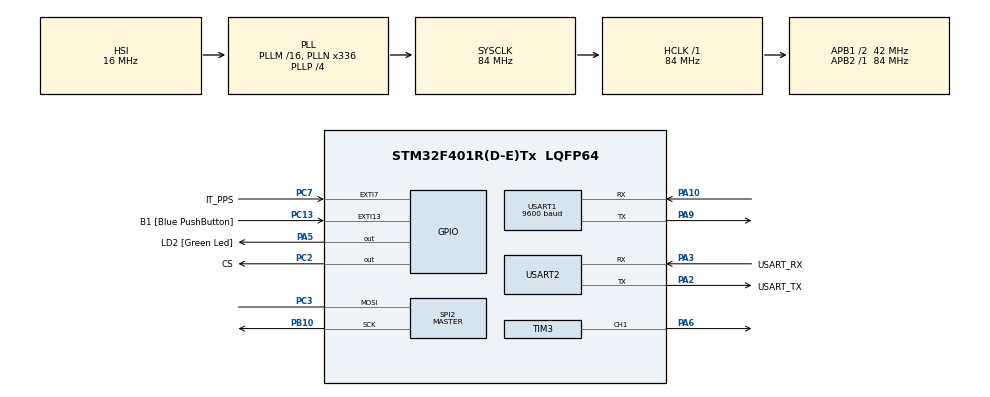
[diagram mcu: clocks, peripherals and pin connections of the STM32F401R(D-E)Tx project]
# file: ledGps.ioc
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Mcu.Family=STM32F4
Mcu.Name=STM32F401R(D-E)Tx
Mcu.Package=LQFP64
NVIC.EXTI9_5_IRQn=true\:0\:0\:false\:false\:true\:true\:true
NVIC.PriorityGroup=NVIC_PRIORITYGROUP_0
NVIC.TIM3_IRQn=true\:0\:0\:false\:false\:true\:true\:true
PA10.Mode=Asynchronous
PA10.Signal=USART1_RX
PA13.GPIO_Label=TMS
PA13.Mode=Serial_Wire
PA13.Signal=SYS_JTMS-SWDIO
PA14.GPIO_Label=TCK
PA14.Mode=Serial_Wire
PA14.Signal=SYS_JTCK-SWCLK
PA2.GPIO_Label=USART_TX
PA2.GPIO_Mode=GPIO_MODE_AF_PP
PA2.GPIO_PuPd=GPIO_NOPULL
PA2.GPIO_Speed=GPIO_SPEED_FREQ_LOW
PA2.Mode=Asynchronous
PA2.Signal=USART2_TX
PA3.GPIO_Label=USART_RX
PA3.GPIO_Mode=GPIO_MODE_AF_PP
PA3.GPIO_PuPd=GPIO_NOPULL
PA3.GPIO_Speed=GPIO_SPEED_FREQ_LOW
PA3.Mode=Asynchronous
PA3.Signal=USART2_RX
PA5.GPIO_Label=LD2 [Green Led]
PA5.GPIO_Mode=GPIO_MODE_OUTPUT_PP
PA5.GPIO_PuPd=GPIO_NOPULL
PA5.GPIO_Speed=GPIO_SPEED_FREQ_LOW
PA5.Signal=GPIO_Output
PA6.Signal=S_TIM3_CH1
PA9.Mode=Asynchronous
PA9.Signal=USART1_TX
PB10.Mode=Simplex_Bidirectional_Master
PB10.Signal=SPI2_SCK
PB3.GPIO_Label=SWO
PB3.Signal=SYS_JTDO-SWO
PC13-ANTI_TAMP.GPIO_Label=B1 [Blue PushButton]
PC13-ANTI_TAMP.GPIO_ModeDefaultEXTI=GPIO_MODE_IT_FALLING
PC13-ANTI_TAMP.GPIO_PuPd=GPIO_NOPULL
PC13-ANTI_TAMP.Signal=GPXTI13
PC14-OSC32_IN.Mode=LSE-External-Oscillator
PC14-OSC32_IN.Signal=RCC_OSC32_IN
PC15-OSC32_OUT.Mode=LSE-External-Oscillator
PC15-OSC32_OUT.Signal=RCC_OSC32_OUT
PC2.GPIO_Label=CS
PC2.GPIO_Speed=GPIO_SPEED_FREQ_VERY_HIGH
PC2.Signal=GPIO_Output
PC3.Mode=Simplex_Bidirectional_Master
PC3.Signal=SPI2_MOSI
PC7.GPIO_Label=IT_PPS
PC7.GPIO_ModeDefaultEXTI=GPIO_MODE_IT_RISING
PC7.Signal=GPXTI7
PH0\ -\ OSC_IN.Mode=HSE-External-Clock-Source
PH0\ -\ OSC_IN.Signal=RCC_OSC_IN
PH1\ -\ OSC_OUT.Mode=HSE-External-Clock-Source
PH1\ -\ OSC_OUT.Signal=RCC_OSC_OUT
ProjectManager.HeapSize=0x200
ProjectManager.StackSize=0x400
ProjectManager.TargetToolchain=Makefile
RCC.48MHZClocksFreq_Value=48000000
RCC.AHBFreq_Value=84000000
RCC.APB1CLKDivider=RCC_HCLK_DIV2
RCC.APB1Freq_Value=42000000
RCC.APB1TimFreq_Value=84000000
RCC.APB2Freq_Value=84000000
RCC.APB2TimFreq_Value=84000000
RCC.CortexFreq_Value=84000000
RCC.HCLKFreq_Value=84000000
RCC.HSE_VALUE=8000000
RCC.HSI_VALUE=16000000
RCC.PLLN=336
RCC.PLLP=RCC_PLLP_DIV4
RCC.PLLQ=7
RCC.SYSCLKFreq_VALUE=84000000
RCC.SYSCLKSource=RCC_SYSCLKSOURCE_PLLCLK
RCC.VCOOutputFreq_Value=336000000
SH.S_TIM3_CH1.0=TIM3_CH1,PWM Generation1 CH1
SPI2.BaudRatePrescaler=SPI_BAUDRATEPRESCALER_128
SPI2.DataSize=SPI_DATASIZE_16BIT
SPI2.Direction=SPI_DIRECTION_1LINE
SPI2.Mode=SPI_MODE_MASTER
SPI2.VirtualType=VM_MASTER
TIM3.Channel-PWM\ Generation1\ CH1=TIM_CHANNEL_1
TIM3.OCFastMode_PWM-PWM\ Generation1\ CH1=TIM_OCFAST_ENABLE
TIM3.Period=10-1
TIM3.Prescaler=840
TIM3.Pulse-PWM\ Generation1\ CH1=5
USART1.BaudRate=9600
USART1.VirtualMode=VM_ASYNC
USART2.VirtualMode=VM_ASYNC
VP_TIM3_VS_ClockSourceINT.Mode=Internal
board=NUCLEO-F401RE

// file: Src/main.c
/* USER CODE BEGIN Header */
/**
  ******************************************************************************
  * @file           : main.c
  * @brief          : Main program body
  ******************************************************************************
  ** This notice applies to any and all portions of this file
  * that are not between comment pairs USER CODE BEGIN and
  * USER CODE END. Other portions of this file, whether
  * inserted by the user or by software development tools
  * are owned by their respective copyright owners.
  *
  * COPYRIGHT(c) 2019 STMicroelectronics
  *
  * Redistribution and use in source and binary forms, with or without modification,
  * are permitted provided that the following conditions are met:
  *   1. Redistributions of source code must retain the above copyright notice,
  *      this list of conditions and the following disclaimer.
  *   2. Redistributions in binary form must reproduce the above copyright notice,
  *      this list of conditions and the following disclaimer in the documentation
  *      and/or other materials provided with the distribution.
  *   3. Neither the name of STMicroelectronics nor the names of its contributors
  *      may be used to endorse or promote products derived from this software
  *      without specific prior written permission.
  *
  * THIS SOFTWARE IS PROVIDED BY THE COPYRIGHT HOLDERS AND CONTRIBUTORS "AS IS"
  * AND ANY EXPRESS OR IMPLIED WARRANTIES, INCLUDING, BUT NOT LIMITED TO, THE
  * IMPLIED WARRANTIES OF MERCHANTABILITY AND FITNESS FOR A PARTICULAR PURPOSE ARE
  * DISCLAIMED. IN NO EVENT SHALL THE COPYRIGHT HOLDER OR CONTRIBUTORS BE LIABLE
  * FOR ANY DIRECT, INDIRECT, INCIDENTAL, SPECIAL, EXEMPLARY, OR CONSEQUENTIAL
  * DAMAGES (INCLUDING, BUT NOT LIMITED TO, PROCUREMENT OF SUBSTITUTE GOODS OR
  * SERVICES; LOSS OF USE, DATA, OR PROFITS; OR BUSINESS INTERRUPTION) HOWEVER
  * CAUSED AND ON ANY THEORY OF LIABILITY, WHETHER IN CONTRACT, STRICT LIABILITY,
  * OR TORT (INCLUDING NEGLIGENCE OR OTHERWISE) ARISING IN ANY WAY OUT OF THE USE
  * OF THIS SOFTWARE, EVEN IF ADVISED OF THE POSSIBILITY OF SUCH DAMAGE.
  *
  ******************************************************************************
  */
/* USER CODE END Header */

#include "main.h"
#include "gpio.h"
#include "spi.h"
#include "tim.h"
#include "usart.h"

/* USER CODE BEGIN Includes */
#include "7seg.h"
#include "Gps.h"
#include <stdlib.h>
/* USER CODE END Includes */

void SystemClock_Config(void);

char message[80] = "\0";
int main(void)
{
    /* USER CODE BEGIN 1 */
    token = (char*)calloc(6, sizeof(char));
    char data[] = "441";
    char* ggaParsed;
    /* USER CODE END 1 */

    /* MCU Configuration--------------------------------------------------------*/

    /* Reset of all peripherals, Initializes the Flash interface and the Systick. */
    HAL_Init();

    /* Configure the system clock */
    SystemClock_Config();

    /* Initialize all configured peripherals */
    MX_GPIO_Init();
    MX_USART2_UART_Init();
    MX_USART1_UART_Init();
    MX_SPI2_Init();
    MX_TIM3_Init();
    /* USER CODE BEGIN 2 */
    HAL_TIM_Base_Start_IT(&htim3);
    /* USER CODE END 2 */

    /* Infinite loop */
    /* USER CODE BEGIN WHILE */
    HAL_GPIO_WritePin(seg_pin.cs_port, seg_pin.cs_pin, 1);
    setupSeg(seg_pin);
    while (1)
    {
        /* USER CODE END WHILE */

        /* USER CODE BEGIN 3 */
        //get gps time
        //on timer tic write uart2

        if (HAL_UART_Receive(&huart1, message, 79,500) == HAL_OK)
        {
            ggaParsed = GgaStringTime(message);
            if (ggaParsed != NULL)
            {
                __disable_irq();
                memcpy(token, ggaParsed, 6*sizeof(char));
                __enable_irq();

            }
        }
    }
    /* USER CODE END 3 */
}

void SystemClock_Config(void)
{
    RCC_OscInitTypeDef RCC_OscInitStruct = { 0 };
    RCC_ClkInitTypeDef RCC_ClkInitStruct = { 0 };

    /** Configure the main internal regulator output voltage
  */
    __HAL_RCC_PWR_CLK_ENABLE();
    __HAL_PWR_VOLTAGESCALING_CONFIG(PWR_REGULATOR_VOLTAGE_SCALE2);
    /** Initializes the CPU, AHB and APB busses clocks
  */
    RCC_OscInitStruct.OscillatorType = RCC_OSCILLATORTYPE_HSI;
    RCC_OscInitStruct.HSIState = RCC_HSI_ON;
    RCC_OscInitStruct.HSICalibrationValue = RCC_HSICALIBRATION_DEFAULT;
    RCC_OscInitStruct.PLL.PLLState = RCC_PLL_ON;
    RCC_OscInitStruct.PLL.PLLSource = RCC_PLLSOURCE_HSI;
    RCC_OscInitStruct.PLL.PLLM = 16;
    RCC_OscInitStruct.PLL.PLLN = 336;
    RCC_OscInitStruct.PLL.PLLP = RCC_PLLP_DIV4;
    RCC_OscInitStruct.PLL.PLLQ = 7;
    if (HAL_RCC_OscConfig(&RCC_OscInitStruct) != HAL_OK)
    {
        Error_Handler();
    }
    /** Initializes the CPU, AHB and APB busses clocks
  */
    RCC_ClkInitStruct.ClockType = RCC_CLOCKTYPE_HCLK | RCC_CLOCKTYPE_SYSCLK
        | RCC_CLOCKTYPE_PCLK1 | RCC_CLOCKTYPE_PCLK2;
    RCC_ClkInitStruct.SYSCLKSource = RCC_SYSCLKSOURCE_PLLCLK;
    RCC_ClkInitStruct.AHBCLKDivider = RCC_SYSCLK_DIV1;
    RCC_ClkInitStruct.APB1CLKDivider = RCC_HCLK_DIV2;
    RCC_ClkInitStruct.APB2CLKDivider = RCC_HCLK_DIV1;

    if (HAL_RCC_ClockConfig(&RCC_ClkInitStruct, FLASH_LATENCY_2) != HAL_OK)
    {
        Error_Handler();
    }
}

void Error_Handler(void)
{
}

/************************ (C) COPYRIGHT STMicroelectronics *****END OF FILE****/
